# R7FA0L107 register map
Vendor: Renesas Electronics Corporation; Series: RA0; File version: 1.10.01
CPU: CM23 r1p0, little endian, no MPU, no FPU, VTOR, 2 interrupt priority bits, 64 interrupts
Registers are 16-bit, read-write, reset 0x0 unless marked. A register's access mark holds for its fields unless they carry their own. Offsets are from the block's base; [hi:lo] are bit positions; {n}, {i} and the like mark numbered series; <NAME> marks a mode.

## ADC_D — A/D Converter
Base 0x400A1800
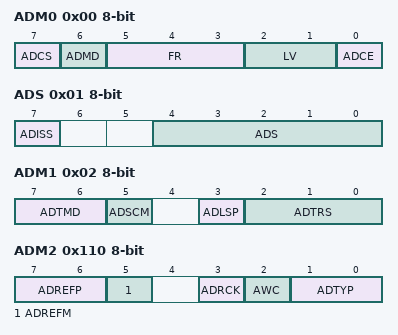
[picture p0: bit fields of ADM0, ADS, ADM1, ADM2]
0x00 ADM0 8-bit — A/D Converter Mode Register 0
  [7] ADCS — A/D conversion operation control
    0=Stops conversion operation [When read] Conversion is stopped or in standby; 1=Enables conversion operation [When read] While in the no wait mode (both software and hardware trigger mode):Conversion is enabledWhile in the wait mode (both software and hardware trigger mode):A/D power supply stabilization wait time + conversion
  [6] ADMD — Specification of the A/D conversion channel selection mode
    0=Select mode; 1=Scan mode
  [5:3] FR — Select Conversion Clock (fAD)
    0=PCLKB/32; 1=PCLKB/16; 2=PCLKB/8; 3=PCLKB/4; 4=PCLKB/2; 5=PCLKB; other=Others (Setting prohibited.)
  [2:1] LV — Select Operation voltage mode
    0=Normal mode 1; 1=Normal mode 2; 2=Low voltage mode 1; 3=Low voltage mode 2
  [0] ADCE — A/D voltage comparator operation control
    0=Stops A/D voltage comparator operation; 1=Enables A/D voltage comparator operation
0x01 ADS 8-bit — Analog Input Channel Specification Register
  [7] ADISS — Select Internal or External of Analog Input (See to )
    0=External input; 1=Internal circuit input
  [4:0] ADS — Selection of the Analog Input Channel (See to )
0x02 ADM1 8-bit — A/D Converter Mode Register 1
  [7:6] ADTMD — Selection of the A/D Conversion Trigger Mode
    2=Hardware trigger no-wait mode; 3=Hardware trigger wait mode; other=Others (Software trigger no-wait mode or software trigger wait mode)
  [5] ADSCM — Specification of the A/D Conversion Mode
    0=Sequential conversion mode; 1=One-shot conversion mode
  [3] ADLSP — PCLKB Input Frequency Setting
    0=4 MHz < PCLKB ≤ 32 MHz; 1=1 MHz ≤ PCLKB ≤ 4 MHz
  [2:0] ADTRS — Selection of the Hardware Trigger Signal
    0=Timer Array Unit channel 1 count or capture end interrupt signal (TAU0_TMI01); 2=Realtime clock interrupt signal (RTC_ALM_OR_PRD); 3=32-bit interval timer event signal (ADITL0 (= TML32_ITL0)); 4=Event input signal (ELC_AD); other=Others (Setting prohibited.)
0x06 ADCR ro — 12-bit or 10-bit A/D Conversion Result Register
0x07 ADCRH 8-bit ro — 8-bit A/D Conversion Result Register
0x110 ADM2 8-bit — A/D Converter Mode Register 2
  [7:6] ADREFP
    0=Supplied from VCC; 1=Supplied from VREFH0/AN000; 2=Supplied from the internal reference voltage; 3=Discharge the internal circuitry
  [5] ADREFM
    0=Supplied from VSS; 1=Supplied from VREFL0/AN001
  [3] ADRCK
    0=The interrupt signal (ADC12_ADI) is output when the ADLL register ≤ the ADCRn register ≤ the ADUL register (AREA 1); 1=The interrupt signal (ADC12_ADI) is output when the ADCRn register < the ADLL register (AREA 2) or the ADUL register < the ADCRn register (AREA 3)
  [2] AWC
    0=Do not use the Snooze mode function; 1=Use the Snooze mode function
  [1:0] ADTYP
    0=10-bit resolution; 1=8-bit resolution; 2=12-bit resolution; other=Others (Setting prohibited.)
0x111 ADUL 8-bit reset 0xFF — Conversion Result Comparison Upper Limit Setting Register
0x112 ADLL 8-bit — Conversion Result Comparison Lower Limit Setting Register
0x113 ADTES 8-bit — A/D Test Register
  [1:0] ADTES — Selection of A/D Conversion Target for Testing
    0=ANxxx, CTSU TSCAP voltage, temperature sensor output voltage or internal reference voltage (Set by analog input channel specification register (ADS)); 2=The ‘-’ side reference voltage (selected by the ADREFM bit of the ADM2 register); 3=The ‘+’ side reference voltage (selected by the ADREFP[1:0] bits of the ADM2 register); other=Others (Setting prohibited.)
{0x120+2i} ADCR{i} ro (i=0..3) — 12-bit or 10-bit A/D Conversion Result Register {i}
{0x121+2i} ADCR{i}H 8-bit ro (i=0..3) — 8-bit A/D Conversion Result Register {i}
